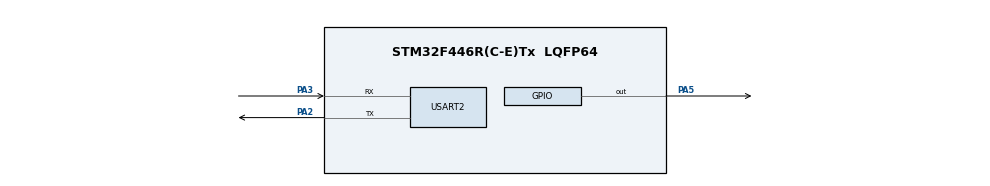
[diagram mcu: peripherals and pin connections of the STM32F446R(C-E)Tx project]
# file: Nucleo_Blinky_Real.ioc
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Mcu.Family=STM32F4
Mcu.Name=STM32F446R(C-E)Tx
Mcu.Package=LQFP64
NVIC.PriorityGroup=NVIC_PRIORITYGROUP_4
NVIC.TIM2_IRQn=true\:0\:0\:false\:false\:true\:true\:true\:true
NVIC.USART2_IRQn=true\:0\:0\:false\:false\:true\:true\:true\:true
PA2.Mode=Asynchronous
PA2.Signal=USART2_TX
PA3.Mode=Asynchronous
PA3.Signal=USART2_RX
PA5.Signal=GPIO_Output
ProjectManager.HeapSize=0x200
ProjectManager.StackSize=0x400
ProjectManager.TargetToolchain=STM32CubeIDE
RCC.CortexFreq_Value=16000000
RCC.USBFreq_Value=96000000
RCC.VCOOutputFreq_Value=192000000
TIM2.Prescaler=15
USART2.VirtualMode=VM_ASYNC
VP_TIM2_VS_ClockSourceINT.Mode=Internal
board=NUCLEO-F446RE

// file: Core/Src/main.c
/* USER CODE BEGIN Header */
/**
  ******************************************************************************
  * @file           : main.c
  * @brief          : Main program body
  ******************************************************************************
  * @attention
  *
  * Copyright (c) 2026 STMicroelectronics.
  * All rights reserved.
  *
  * This software is licensed under terms that can be found in the LICENSE file
  * in the root directory of this software component.
  * If no LICENSE file comes with this software, it is provided AS-IS.
  *
  ******************************************************************************
  */
/* USER CODE END Header */
#include "main.h"
#include <string.h>

/* USER CODE BEGIN Includes */
/* USER CODE BEGIN PD */
#define OP_TOGGLE_PIN 1

typedef struct __attribute__((packed)) {
    uint32_t task_id;
    uint64_t exec_time_us;
    uint8_t  opcode;
    uint8_t  pin_num;
} rt_task_t;

typedef struct __attribute__((packed)) {
    uint32_t task_id;
    uint8_t  status;
} rt_result_t;

#define RT_TASK_SIZE   sizeof(rt_task_t)    /* Exactly 14 bytes */
#define RT_RESULT_SIZE sizeof(rt_result_t)  /* Exactly 5 bytes  */
/* USER CODE END PD */
/* USER CODE END Includes */

TIM_HandleTypeDef htim2;

UART_HandleTypeDef huart2;

/* USER CODE BEGIN PV */
uint8_t uart_rx_buf[14];  /* Data loading dock */
volatile rt_task_t active_task;      /* Holds the current running job */
volatile uint8_t task_armed   = 0; /* Is the timer running right now? */
volatile uint8_t result_ready = 0; /* Set when done, tells main loop to reply */
/* USER CODE END PV */

void SystemClock_Config(void);
static void MX_GPIO_Init(void);
static void MX_TIM2_Init(void);
static void MX_USART2_UART_Init(void);

int main(void)
{

  /* MCU Configuration--------------------------------------------------------*/

  /* Reset of all peripherals, Initializes the Flash interface and the Systick. */
  HAL_Init();

  /* Configure the system clock */
  SystemClock_Config();

  /* Initialize all configured peripherals */
  MX_GPIO_Init();
  MX_TIM2_Init();
  MX_USART2_UART_Init();
  /* USER CODE BEGIN 2 */

    /* Clear any stale interrupt flags before booting up the listener */
    __HAL_TIM_CLEAR_IT(&htim2, TIM_IT_UPDATE);

    /* Tell the hardware to wait for exactly 14 bytes asynchronously */
    HAL_UART_Receive_IT(&huart2, uart_rx_buf, RT_TASK_SIZE);

    /* USER CODE END 2 */

  /* Infinite loop */
  /* USER CODE BEGIN WHILE */
  while (1)
    {
      /* The main loop stands by until an interrupt sets 'result_ready' */
      if (result_ready) {
          result_ready = 0;

          /* DIAGNOSTIC HEARTBEAT:
           * If we successfully processed an ioctl task from Linux,
           * briefly force the LED on for 50 milliseconds so we can see it blink! */
          HAL_GPIO_WritePin(GPIOA, GPIO_PIN_5, GPIO_PIN_SET);
          HAL_Delay(50);
          HAL_GPIO_WritePin(GPIOA, GPIO_PIN_5, GPIO_PIN_RESET);

          rt_result_t result;
          result.task_id = active_task.task_id;
          result.status  = 0;  /* 0 = Success status code */

          /* Transmit the 5-byte receipt back to your laptop */
          HAL_UART_Transmit(&huart2, (uint8_t*)&result, RT_RESULT_SIZE, 100);
          HAL_UART_Receive_IT(&huart2, uart_rx_buf, sizeof(rt_task_t));
      }
      /* USER CODE END WHILE */

    }
}

void SystemClock_Config(void)
{
  RCC_OscInitTypeDef RCC_OscInitStruct = {0};
  RCC_ClkInitTypeDef RCC_ClkInitStruct = {0};

  /** Configure the main internal regulator output voltage
  */
  __HAL_RCC_PWR_CLK_ENABLE();
  __HAL_PWR_VOLTAGESCALING_CONFIG(PWR_REGULATOR_VOLTAGE_SCALE3);

  /** Initializes the RCC Oscillators according to the specified parameters
  * in the RCC_OscInitTypeDef structure.
  */
  RCC_OscInitStruct.OscillatorType = RCC_OSCILLATORTYPE_HSI;
  RCC_OscInitStruct.HSIState = RCC_HSI_ON;
  RCC_OscInitStruct.HSICalibrationValue = RCC_HSICALIBRATION_DEFAULT;
  RCC_OscInitStruct.PLL.PLLState = RCC_PLL_NONE;
  if (HAL_RCC_OscConfig(&RCC_OscInitStruct) != HAL_OK)
  {
    Error_Handler();
  }

  /** Initializes the CPU, AHB and APB buses clocks
  */
  RCC_ClkInitStruct.ClockType = RCC_CLOCKTYPE_HCLK|RCC_CLOCKTYPE_SYSCLK
                              |RCC_CLOCKTYPE_PCLK1|RCC_CLOCKTYPE_PCLK2;
  RCC_ClkInitStruct.SYSCLKSource = RCC_SYSCLKSOURCE_HSI;
  RCC_ClkInitStruct.AHBCLKDivider = RCC_SYSCLK_DIV1;
  RCC_ClkInitStruct.APB1CLKDivider = RCC_HCLK_DIV1;
  RCC_ClkInitStruct.APB2CLKDivider = RCC_HCLK_DIV1;

  if (HAL_RCC_ClockConfig(&RCC_ClkInitStruct, FLASH_LATENCY_0) != HAL_OK)
  {
    Error_Handler();
  }
}

static void MX_TIM2_Init(void)
{

  TIM_ClockConfigTypeDef sClockSourceConfig = {0};
  TIM_MasterConfigTypeDef sMasterConfig = {0};

  htim2.Instance = TIM2;
  htim2.Init.Prescaler = 15;
  htim2.Init.CounterMode = TIM_COUNTERMODE_UP;
  htim2.Init.Period = 4294967295;
  htim2.Init.ClockDivision = TIM_CLOCKDIVISION_DIV1;
  htim2.Init.AutoReloadPreload = TIM_AUTORELOAD_PRELOAD_DISABLE;
  if (HAL_TIM_Base_Init(&htim2) != HAL_OK)
  {
    Error_Handler();
  }
  sClockSourceConfig.ClockSource = TIM_CLOCKSOURCE_INTERNAL;
  if (HAL_TIM_ConfigClockSource(&htim2, &sClockSourceConfig) != HAL_OK)
  {
    Error_Handler();
  }
  sMasterConfig.MasterOutputTrigger = TIM_TRGO_RESET;
  sMasterConfig.MasterSlaveMode = TIM_MASTERSLAVEMODE_DISABLE;
  if (HAL_TIMEx_MasterConfigSynchronization(&htim2, &sMasterConfig) != HAL_OK)
  {
    Error_Handler();
  }

}

static void MX_USART2_UART_Init(void)
{

  huart2.Instance = USART2;
  huart2.Init.BaudRate = 115200;
  huart2.Init.WordLength = UART_WORDLENGTH_8B;
  huart2.Init.StopBits = UART_STOPBITS_1;
  huart2.Init.Parity = UART_PARITY_NONE;
  huart2.Init.Mode = UART_MODE_TX_RX;
  huart2.Init.HwFlowCtl = UART_HWCONTROL_NONE;
  huart2.Init.OverSampling = UART_OVERSAMPLING_16;
  if (HAL_UART_Init(&huart2) != HAL_OK)
  {
    Error_Handler();
  }

}

static void MX_GPIO_Init(void)
{
  GPIO_InitTypeDef GPIO_InitStruct = {0};

  /* GPIO Ports Clock Enable */
  __HAL_RCC_GPIOA_CLK_ENABLE();

  /*Configure GPIO pin Output Level */
  HAL_GPIO_WritePin(GPIOA, GPIO_PIN_5, GPIO_PIN_RESET);

  /*Configure GPIO pin : PA5 */
  GPIO_InitStruct.Pin = GPIO_PIN_5;
  GPIO_InitStruct.Mode = GPIO_MODE_OUTPUT_PP;
  GPIO_InitStruct.Pull = GPIO_NOPULL;
  GPIO_InitStruct.Speed = GPIO_SPEED_FREQ_LOW;
  HAL_GPIO_Init(GPIOA, &GPIO_InitStruct);

}

/* USER CODE BEGIN 4 */

/**
 * Fires automatically when the serial port finishes collecting 14 bytes from Linux.
 */
void HAL_UART_RxCpltCallback(UART_HandleTypeDef *huart)
{
    if (huart->Instance == USART2) {
        memcpy((void*)&active_task, uart_rx_buf, sizeof(rt_task_t));

        uint32_t delay_ticks = (uint32_t)active_task.exec_time_us;
        if (delay_ticks == 0) delay_ticks = 1;

        HAL_TIM_Base_Stop_IT(&htim2);
        __HAL_TIM_SET_COUNTER(&htim2, 0);
        __HAL_TIM_SET_AUTORELOAD(&htim2, delay_ticks);

        task_armed = 1;
        HAL_TIM_Base_Start_IT(&htim2);
        /* Notice: No Receive_IT here! */
    }
}

void HAL_UART_ErrorCallback(UART_HandleTypeDef *huart)
{
    if (huart->Instance == USART2) {
        /* On the STM32F4, we clear these errors using their dedicated F4 HAL macros */
        if (__HAL_UART_GET_FLAG(huart, UART_FLAG_ORE) != RESET) {
            __HAL_UART_CLEAR_OREFLAG(huart);
        }
        if (__HAL_UART_GET_FLAG(huart, UART_FLAG_NE) != RESET) {
            __HAL_UART_CLEAR_NEFLAG(huart);
        }
        if (__HAL_UART_GET_FLAG(huart, UART_FLAG_FE) != RESET) {
            __HAL_UART_CLEAR_FEFLAG(huart);
        }

        /* Re-arm the receiver to keep the pipeline alive */
        HAL_UART_Receive_IT(huart, uart_rx_buf, sizeof(rt_task_t));
    }
}

void HAL_TIM_PeriodElapsedCallback(TIM_HandleTypeDef *htim)
{
    if (htim->Instance == TIM2) {
        if (task_armed) {
            HAL_TIM_Base_Stop_IT(&htim2);
            HAL_GPIO_TogglePin(GPIOA, GPIO_PIN_5); /* Toggle LED */

            task_armed = 0;
            result_ready = 1; /* Tell main loop to transmit */
        }
    }
}

/* USER CODE END 4 */

void Error_Handler(void)
{
  __disable_irq();
  while (1)
  {
  }
}
